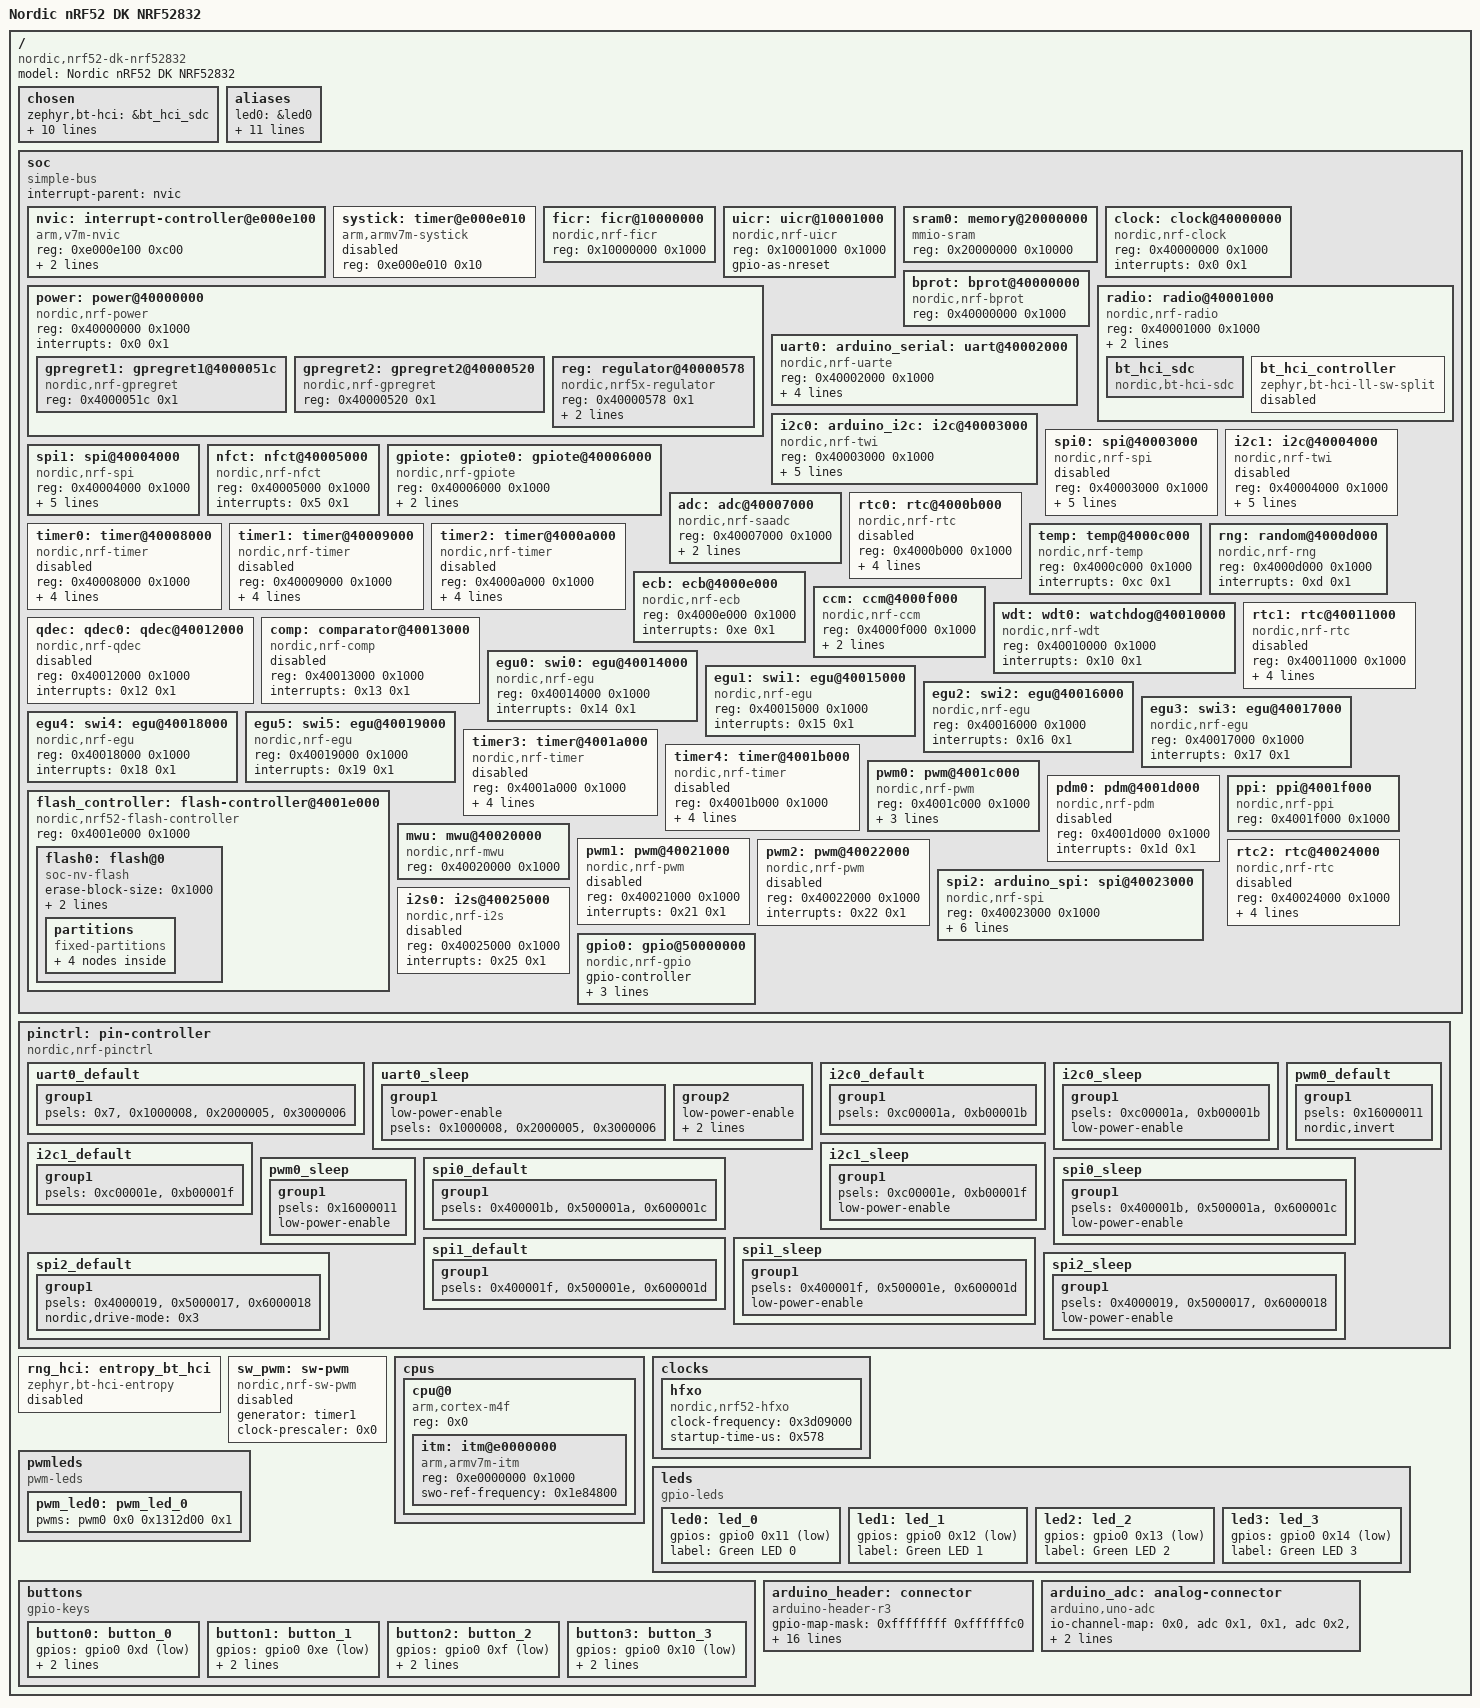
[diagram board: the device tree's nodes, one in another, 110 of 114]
/dts-v1/;

/* node '/' defined in zephyr/dts/common/skeleton.dtsi:9 */
/ {
	#address-cells = < 0x1 >;                /* in zephyr/dts/common/skeleton.dtsi:10 */
	#size-cells = < 0x1 >;                   /* in zephyr/dts/common/skeleton.dtsi:11 */
	model = "Nordic nRF52 DK NRF52832";      /* in zephyr/boards/nordic/nrf52dk/nrf52dk_nrf52832.dts:15 */
	compatible = "nordic,nrf52-dk-nrf52832"; /* in zephyr/boards/nordic/nrf52dk/nrf52dk_nrf52832.dts:16 */

	/* node '/chosen' defined in zephyr/dts/common/skeleton.dtsi:13 */
	chosen {
		zephyr,bt-hci = &bt_hci_sdc;                 /* in zephyr/dts/arm/nordic/nrf52832.dtsi:14 */
		zephyr,entropy = &rng;                       /* in zephyr/dts/arm/nordic/nrf52832.dtsi:15 */
		zephyr,flash-controller = &flash_controller; /* in zephyr/dts/arm/nordic/nrf52832.dtsi:16 */
		zephyr,console = &uart0;                     /* in zephyr/boards/nordic/nrf52dk/nrf52dk_nrf52832.dts:19 */
		zephyr,shell-uart = &uart0;                  /* in zephyr/boards/nordic/nrf52dk/nrf52dk_nrf52832.dts:20 */
		zephyr,uart-mcumgr = &uart0;                 /* in zephyr/boards/nordic/nrf52dk/nrf52dk_nrf52832.dts:21 */
		zephyr,bt-mon-uart = &uart0;                 /* in zephyr/boards/nordic/nrf52dk/nrf52dk_nrf52832.dts:22 */
		zephyr,bt-c2h-uart = &uart0;                 /* in zephyr/boards/nordic/nrf52dk/nrf52dk_nrf52832.dts:23 */
		zephyr,sram = &sram0;                        /* in zephyr/boards/nordic/nrf52dk/nrf52dk_nrf52832.dts:24 */
		zephyr,flash = &flash0;                      /* in zephyr/boards/nordic/nrf52dk/nrf52dk_nrf52832.dts:25 */
		zephyr,code-partition = &slot0_partition;    /* in zephyr/boards/nordic/nrf52dk/nrf52dk_nrf52832.dts:26 */
	};

	/* node '/aliases' defined in zephyr/dts/common/skeleton.dtsi:15 */
	aliases {
		led0 = &led0;               /* in zephyr/boards/nordic/nrf52dk/nrf52dk_nrf52832.dts:131 */
		led1 = &led1;               /* in zephyr/boards/nordic/nrf52dk/nrf52dk_nrf52832.dts:132 */
		led2 = &led2;               /* in zephyr/boards/nordic/nrf52dk/nrf52dk_nrf52832.dts:133 */
		led3 = &led3;               /* in zephyr/boards/nordic/nrf52dk/nrf52dk_nrf52832.dts:134 */
		pwm-led0 = &pwm_led0;       /* in zephyr/boards/nordic/nrf52dk/nrf52dk_nrf52832.dts:135 */
		sw0 = &button0;             /* in zephyr/boards/nordic/nrf52dk/nrf52dk_nrf52832.dts:136 */
		sw1 = &button1;             /* in zephyr/boards/nordic/nrf52dk/nrf52dk_nrf52832.dts:137 */
		sw2 = &button2;             /* in zephyr/boards/nordic/nrf52dk/nrf52dk_nrf52832.dts:138 */
		sw3 = &button3;             /* in zephyr/boards/nordic/nrf52dk/nrf52dk_nrf52832.dts:139 */
		mcuboot-button0 = &button0; /* in zephyr/boards/nordic/nrf52dk/nrf52dk_nrf52832.dts:140 */
		mcuboot-led0 = &led0;       /* in zephyr/boards/nordic/nrf52dk/nrf52dk_nrf52832.dts:141 */
		watchdog0 = &wdt0;          /* in zephyr/boards/nordic/nrf52dk/nrf52dk_nrf52832.dts:142 */
	};

	/* node '/soc' defined in zephyr/dts/arm/armv7-m.dtsi:6 */
	soc {
		#address-cells = < 0x1 >;     /* in zephyr/dts/arm/armv7-m.dtsi:7 */
		#size-cells = < 0x1 >;        /* in zephyr/dts/arm/armv7-m.dtsi:8 */
		interrupt-parent = < &nvic >; /* in zephyr/dts/arm/armv7-m.dtsi:10 */
		ranges;                       /* in zephyr/dts/arm/armv7-m.dtsi:11 */
		compatible = "simple-bus";    /* in zephyr/dts/arm/nordic/nrf52832_qfaa.dtsi:21 */

		/* node '/soc/interrupt-controller@e000e100' defined in zephyr/dts/arm/armv7-m.dtsi:13 */
		nvic: interrupt-controller@e000e100 {
			#address-cells = < 0x1 >;            /* in zephyr/dts/arm/armv7-m.dtsi:14 */
			compatible = "arm,v7m-nvic";         /* in zephyr/dts/arm/armv7-m.dtsi:15 */
			reg = < 0xe000e100 0xc00 >;          /* in zephyr/dts/arm/armv7-m.dtsi:16 */
			interrupt-controller;                /* in zephyr/dts/arm/armv7-m.dtsi:17 */
			#interrupt-cells = < 0x2 >;          /* in zephyr/dts/arm/armv7-m.dtsi:18 */
			arm,num-irq-priority-bits = < 0x3 >; /* in zephyr/dts/arm/nordic/nrf52832.dtsi:510 */
			phandle = < 0x1 >;                   /* in zephyr/dts/arm/armv7-m.dtsi:10 */
		};

		/* node '/soc/timer@e000e010' defined in zephyr/dts/arm/armv7-m.dtsi:21 */
		systick: timer@e000e010 {
			compatible = "arm,armv7m-systick"; /* in zephyr/dts/arm/armv7-m.dtsi:22 */
			reg = < 0xe000e010 0x10 >;         /* in zephyr/dts/arm/armv7-m.dtsi:23 */
			status = "disabled";               /* in zephyr/dts/arm/nordic/nrf52832.dtsi:515 */
		};

		/* node '/soc/ficr@10000000' defined in zephyr/dts/arm/nordic/nrf52832.dtsi:48 */
		ficr: ficr@10000000 {
			compatible = "nordic,nrf-ficr"; /* in zephyr/dts/arm/nordic/nrf52832.dtsi:49 */
			reg = < 0x10000000 0x1000 >;    /* in zephyr/dts/arm/nordic/nrf52832.dtsi:50 */
			#nordic,ficr-cells = < 0x1 >;   /* in zephyr/dts/arm/nordic/nrf52832.dtsi:51 */
			status = "okay";                /* in zephyr/dts/arm/nordic/nrf52832.dtsi:52 */
		};

		/* node '/soc/uicr@10001000' defined in zephyr/dts/arm/nordic/nrf52832.dtsi:55 */
		uicr: uicr@10001000 {
			compatible = "nordic,nrf-uicr";     /* in zephyr/dts/arm/nordic/nrf52832.dtsi:56 */
			reg = < 0x10001000 0x1000 >;        /* in zephyr/dts/arm/nordic/nrf52832.dtsi:57 */
			ranges = < 0x0 0x10001000 0x1000 >; /* in zephyr/dts/arm/nordic/nrf52832.dtsi:58 */
			status = "okay";                    /* in zephyr/dts/arm/nordic/nrf52832.dtsi:59 */
			#address-cells = < 0x1 >;           /* in zephyr/dts/arm/nordic/nrf52832.dtsi:60 */
			#size-cells = < 0x1 >;              /* in zephyr/dts/arm/nordic/nrf52832.dtsi:61 */
			gpio-as-nreset;                     /* in zephyr/boards/nordic/nrf52dk/nrf52dk_nrf52832.dts:155 */
		};

		/* node '/soc/memory@20000000' defined in zephyr/dts/arm/nordic/nrf52832.dtsi:64 */
		sram0: memory@20000000 {
			compatible = "mmio-sram";            /* in zephyr/dts/arm/nordic/nrf52832.dtsi:65 */
			#address-cells = < 0x1 >;            /* in zephyr/dts/arm/nordic/nrf52832.dtsi:66 */
			#size-cells = < 0x1 >;               /* in zephyr/dts/arm/nordic/nrf52832.dtsi:67 */
			reg = < 0x20000000 0x10000 >;        /* in zephyr/dts/arm/nordic/nrf52832_qfaa.dtsi:15 */
			ranges = < 0x0 0x20000000 0x10000 >; /* in zephyr/dts/arm/nordic/nrf52832_qfaa.dtsi:16 */
		};

		/* node '/soc/clock@40000000' defined in zephyr/dts/arm/nordic/nrf52832.dtsi:70 */
		clock: clock@40000000 {
			compatible = "nordic,nrf-clock"; /* in zephyr/dts/arm/nordic/nrf52832.dtsi:71 */
			reg = < 0x40000000 0x1000 >;     /* in zephyr/dts/arm/nordic/nrf52832.dtsi:72 */
			interrupts = < 0x0 0x1 >;        /* in zephyr/dts/arm/nordic/nrf52832.dtsi:73 */
			status = "okay";                 /* in zephyr/dts/arm/nordic/nrf52832.dtsi:74 */
		};

		/* node '/soc/power@40000000' defined in zephyr/dts/arm/nordic/nrf52832.dtsi:77 */
		power: power@40000000 {
			compatible = "nordic,nrf-power"; /* in zephyr/dts/arm/nordic/nrf52832.dtsi:78 */
			reg = < 0x40000000 0x1000 >;     /* in zephyr/dts/arm/nordic/nrf52832.dtsi:79 */
			interrupts = < 0x0 0x1 >;        /* in zephyr/dts/arm/nordic/nrf52832.dtsi:80 */
			status = "okay";                 /* in zephyr/dts/arm/nordic/nrf52832.dtsi:81 */
			#address-cells = < 0x1 >;        /* in zephyr/dts/arm/nordic/nrf52832.dtsi:82 */
			#size-cells = < 0x1 >;           /* in zephyr/dts/arm/nordic/nrf52832.dtsi:83 */

			/* node '/soc/power@40000000/gpregret1@4000051c' defined in zephyr/dts/arm/nordic/nrf52832.dtsi:85 */
			gpregret1: gpregret1@4000051c {
				#address-cells = < 0x1 >;           /* in zephyr/dts/arm/nordic/nrf52832.dtsi:86 */
				#size-cells = < 0x1 >;              /* in zephyr/dts/arm/nordic/nrf52832.dtsi:87 */
				compatible = "nordic,nrf-gpregret"; /* in zephyr/dts/arm/nordic/nrf52832.dtsi:88 */
				reg = < 0x4000051c 0x1 >;           /* in zephyr/dts/arm/nordic/nrf52832.dtsi:89 */
				status = "okay";                    /* in zephyr/dts/arm/nordic/nrf52832.dtsi:90 */
			};

			/* node '/soc/power@40000000/gpregret2@40000520' defined in zephyr/dts/arm/nordic/nrf52832.dtsi:93 */
			gpregret2: gpregret2@40000520 {
				#address-cells = < 0x1 >;           /* in zephyr/dts/arm/nordic/nrf52832.dtsi:94 */
				#size-cells = < 0x1 >;              /* in zephyr/dts/arm/nordic/nrf52832.dtsi:95 */
				compatible = "nordic,nrf-gpregret"; /* in zephyr/dts/arm/nordic/nrf52832.dtsi:96 */
				reg = < 0x40000520 0x1 >;           /* in zephyr/dts/arm/nordic/nrf52832.dtsi:97 */
				status = "okay";                    /* in zephyr/dts/arm/nordic/nrf52832.dtsi:98 */
			};

			/* node '/soc/power@40000000/regulator@40000578' defined in zephyr/dts/arm/nordic/nrf52832.dtsi:101 */
			reg: regulator@40000578 {
				compatible = "nordic,nrf5x-regulator"; /* in zephyr/dts/arm/nordic/nrf52832.dtsi:102 */
				reg = < 0x40000578 0x1 >;              /* in zephyr/dts/arm/nordic/nrf52832.dtsi:103 */
				regulator-name = "REG";                /* in zephyr/dts/arm/nordic/nrf52832.dtsi:104 */
				regulator-initial-mode = < 0x1 >;      /* in zephyr/boards/nordic/nrf52dk/nrf52dk_nrf52832.dts:147 */
			};
		};

		/* node '/soc/bprot@40000000' defined in zephyr/dts/arm/nordic/nrf52832.dtsi:109 */
		bprot: bprot@40000000 {
			compatible = "nordic,nrf-bprot"; /* in zephyr/dts/arm/nordic/nrf52832.dtsi:110 */
			reg = < 0x40000000 0x1000 >;     /* in zephyr/dts/arm/nordic/nrf52832.dtsi:111 */
			status = "okay";                 /* in zephyr/dts/arm/nordic/nrf52832.dtsi:112 */
		};

		/* node '/soc/radio@40001000' defined in zephyr/dts/arm/nordic/nrf52832.dtsi:115 */
		radio: radio@40001000 {
			compatible = "nordic,nrf-radio"; /* in zephyr/dts/arm/nordic/nrf52832.dtsi:116 */
			reg = < 0x40001000 0x1000 >;     /* in zephyr/dts/arm/nordic/nrf52832.dtsi:117 */
			interrupts = < 0x1 0x1 >;        /* in zephyr/dts/arm/nordic/nrf52832.dtsi:118 */
			status = "okay";                 /* in zephyr/dts/arm/nordic/nrf52832.dtsi:119 */
			ble-2mbps-supported;             /* in zephyr/dts/arm/nordic/nrf52832.dtsi:120 */

			/* node '/soc/radio@40001000/bt_hci_sdc' defined in zephyr/dts/arm/nordic/nrf52832.dtsi:122 */
			bt_hci_sdc: bt_hci_sdc {
				compatible = "nordic,bt-hci-sdc"; /* in zephyr/dts/arm/nordic/nrf52832.dtsi:123 */
				status = "okay";                  /* in zephyr/dts/arm/nordic/nrf52832.dtsi:124 */
			};

			/* node '/soc/radio@40001000/bt_hci_controller' defined in zephyr/dts/arm/nordic/nrf52832.dtsi:126 */
			bt_hci_controller: bt_hci_controller {
				compatible = "zephyr,bt-hci-ll-sw-split"; /* in zephyr/dts/arm/nordic/nrf52832.dtsi:127 */
				status = "disabled";                      /* in zephyr/dts/arm/nordic/nrf52832.dtsi:128 */
			};
		};

		/* node '/soc/uart@40002000' defined in zephyr/dts/arm/nordic/nrf52832.dtsi:132 */
		uart0: arduino_serial: uart@40002000 {
			reg = < 0x40002000 0x1000 >;     /* in zephyr/dts/arm/nordic/nrf52832.dtsi:136 */
			interrupts = < 0x2 0x1 >;        /* in zephyr/dts/arm/nordic/nrf52832.dtsi:137 */
			status = "okay";                 /* in zephyr/boards/nordic/nrf52dk/nrf52dk_nrf52832.dts:171 */
			compatible = "nordic,nrf-uarte"; /* in zephyr/boards/nordic/nrf52dk/nrf52dk_nrf52832.dts:172 */
			current-speed = < 0x1c200 >;     /* in zephyr/boards/nordic/nrf52dk/nrf52dk_nrf52832.dts:173 */
			pinctrl-0 = < &uart0_default >;  /* in zephyr/boards/nordic/nrf52dk/nrf52dk_nrf52832.dts:174 */
			pinctrl-1 = < &uart0_sleep >;    /* in zephyr/boards/nordic/nrf52dk/nrf52dk_nrf52832.dts:175 */
			pinctrl-names = "default",
			                "sleep";         /* in zephyr/boards/nordic/nrf52dk/nrf52dk_nrf52832.dts:176 */
		};

		/* node '/soc/i2c@40003000' defined in zephyr/dts/arm/nordic/nrf52832.dtsi:141 */
		i2c0: arduino_i2c: i2c@40003000 {
			#address-cells = < 0x1 >;      /* in zephyr/dts/arm/nordic/nrf52832.dtsi:150 */
			#size-cells = < 0x0 >;         /* in zephyr/dts/arm/nordic/nrf52832.dtsi:151 */
			reg = < 0x40003000 0x1000 >;   /* in zephyr/dts/arm/nordic/nrf52832.dtsi:152 */
			interrupts = < 0x3 0x1 >;      /* in zephyr/dts/arm/nordic/nrf52832.dtsi:153 */
			easydma-maxcnt-bits = < 0x8 >; /* in zephyr/dts/arm/nordic/nrf52832.dtsi:154 */
			zephyr,pm-device-runtime-auto; /* in zephyr/dts/arm/nordic/nrf52832.dtsi:156 */
			compatible = "nordic,nrf-twi"; /* in zephyr/boards/nordic/nrf52dk/nrf52dk_nrf52832.dts:180 */
			status = "okay";               /* in zephyr/boards/nordic/nrf52dk/nrf52dk_nrf52832.dts:181 */
			pinctrl-0 = < &i2c0_default >; /* in zephyr/boards/nordic/nrf52dk/nrf52dk_nrf52832.dts:182 */
			pinctrl-1 = < &i2c0_sleep >;   /* in zephyr/boards/nordic/nrf52dk/nrf52dk_nrf52832.dts:183 */
			pinctrl-names = "default",
			                "sleep";       /* in zephyr/boards/nordic/nrf52dk/nrf52dk_nrf52832.dts:184 */
		};

		/* node '/soc/spi@40003000' defined in zephyr/dts/arm/nordic/nrf52832.dtsi:159 */
		spi0: spi@40003000 {
			#address-cells = < 0x1 >;      /* in zephyr/dts/arm/nordic/nrf52832.dtsi:168 */
			#size-cells = < 0x0 >;         /* in zephyr/dts/arm/nordic/nrf52832.dtsi:169 */
			reg = < 0x40003000 0x1000 >;   /* in zephyr/dts/arm/nordic/nrf52832.dtsi:170 */
			interrupts = < 0x3 0x1 >;      /* in zephyr/dts/arm/nordic/nrf52832.dtsi:171 */
			max-frequency = < 0x7a1200 >;  /* in zephyr/dts/arm/nordic/nrf52832.dtsi:172 */
			easydma-maxcnt-bits = < 0x8 >; /* in zephyr/dts/arm/nordic/nrf52832.dtsi:173 */
			status = "disabled";           /* in zephyr/dts/arm/nordic/nrf52832.dtsi:174 */
			compatible = "nordic,nrf-spi"; /* in zephyr/boards/nordic/nrf52dk/nrf52dk_nrf52832.dts:204 */
			pinctrl-0 = < &spi0_default >; /* in zephyr/boards/nordic/nrf52dk/nrf52dk_nrf52832.dts:207 */
			pinctrl-1 = < &spi0_sleep >;   /* in zephyr/boards/nordic/nrf52dk/nrf52dk_nrf52832.dts:208 */
			pinctrl-names = "default",
			                "sleep";       /* in zephyr/boards/nordic/nrf52dk/nrf52dk_nrf52832.dts:209 */
		};

		/* node '/soc/i2c@40004000' defined in zephyr/dts/arm/nordic/nrf52832.dtsi:177 */
		i2c1: i2c@40004000 {
			#address-cells = < 0x1 >;      /* in zephyr/dts/arm/nordic/nrf52832.dtsi:186 */
			#size-cells = < 0x0 >;         /* in zephyr/dts/arm/nordic/nrf52832.dtsi:187 */
			reg = < 0x40004000 0x1000 >;   /* in zephyr/dts/arm/nordic/nrf52832.dtsi:188 */
			interrupts = < 0x4 0x1 >;      /* in zephyr/dts/arm/nordic/nrf52832.dtsi:189 */
			easydma-maxcnt-bits = < 0x8 >; /* in zephyr/dts/arm/nordic/nrf52832.dtsi:190 */
			status = "disabled";           /* in zephyr/dts/arm/nordic/nrf52832.dtsi:191 */
			zephyr,pm-device-runtime-auto; /* in zephyr/dts/arm/nordic/nrf52832.dtsi:192 */
			compatible = "nordic,nrf-twi"; /* in zephyr/boards/nordic/nrf52dk/nrf52dk_nrf52832.dts:188 */
			pinctrl-0 = < &i2c1_default >; /* in zephyr/boards/nordic/nrf52dk/nrf52dk_nrf52832.dts:191 */
			pinctrl-1 = < &i2c1_sleep >;   /* in zephyr/boards/nordic/nrf52dk/nrf52dk_nrf52832.dts:192 */
			pinctrl-names = "default",
			                "sleep";       /* in zephyr/boards/nordic/nrf52dk/nrf52dk_nrf52832.dts:193 */
		};

		/* node '/soc/spi@40004000' defined in zephyr/dts/arm/nordic/nrf52832.dtsi:195 */
		spi1: spi@40004000 {
			#address-cells = < 0x1 >;      /* in zephyr/dts/arm/nordic/nrf52832.dtsi:204 */
			#size-cells = < 0x0 >;         /* in zephyr/dts/arm/nordic/nrf52832.dtsi:205 */
			reg = < 0x40004000 0x1000 >;   /* in zephyr/dts/arm/nordic/nrf52832.dtsi:206 */
			interrupts = < 0x4 0x1 >;      /* in zephyr/dts/arm/nordic/nrf52832.dtsi:207 */
			max-frequency = < 0x7a1200 >;  /* in zephyr/dts/arm/nordic/nrf52832.dtsi:208 */
			easydma-maxcnt-bits = < 0x8 >; /* in zephyr/dts/arm/nordic/nrf52832.dtsi:209 */
			compatible = "nordic,nrf-spi"; /* in zephyr/boards/nordic/nrf52dk/nrf52dk_nrf52832.dts:213 */
			status = "okay";               /* in zephyr/boards/nordic/nrf52dk/nrf52dk_nrf52832.dts:214 */
			pinctrl-0 = < &spi1_default >; /* in zephyr/boards/nordic/nrf52dk/nrf52dk_nrf52832.dts:215 */
			pinctrl-1 = < &spi1_sleep >;   /* in zephyr/boards/nordic/nrf52dk/nrf52dk_nrf52832.dts:216 */
			pinctrl-names = "default",
			                "sleep";       /* in zephyr/boards/nordic/nrf52dk/nrf52dk_nrf52832.dts:217 */
		};

		/* node '/soc/nfct@40005000' defined in zephyr/dts/arm/nordic/nrf52832.dtsi:213 */
		nfct: nfct@40005000 {
			compatible = "nordic,nrf-nfct"; /* in zephyr/dts/arm/nordic/nrf52832.dtsi:214 */
			reg = < 0x40005000 0x1000 >;    /* in zephyr/dts/arm/nordic/nrf52832.dtsi:215 */
			interrupts = < 0x5 0x1 >;       /* in zephyr/dts/arm/nordic/nrf52832.dtsi:216 */
			status = "okay";                /* in zephyr/boards/nordic/nrf52dk/nrf52dk_nrf52832.dts:159 */
		};

		/* node '/soc/gpiote@40006000' defined in zephyr/dts/arm/nordic/nrf52832.dtsi:220 */
		gpiote: gpiote0: gpiote@40006000 {
			compatible = "nordic,nrf-gpiote"; /* in zephyr/dts/arm/nordic/nrf52832.dtsi:221 */
			reg = < 0x40006000 0x1000 >;      /* in zephyr/dts/arm/nordic/nrf52832.dtsi:222 */
			interrupts = < 0x6 0x5 >;         /* in zephyr/dts/arm/nordic/nrf52832.dtsi:223 */
			instance = < 0x0 >;               /* in zephyr/dts/arm/nordic/nrf52832.dtsi:225 */
			status = "okay";                  /* in zephyr/boards/nordic/nrf52dk/nrf52dk_nrf52832.dts:163 */
			phandle = < 0x11 >;               /* in zephyr/dts/arm/nordic/nrf52832.dtsi:504 */
		};

		/* node '/soc/adc@40007000' defined in zephyr/dts/arm/nordic/nrf52832.dtsi:228 */
		adc: adc@40007000 {
			compatible = "nordic,nrf-saadc"; /* in zephyr/dts/arm/nordic/nrf52832.dtsi:229 */
			reg = < 0x40007000 0x1000 >;     /* in zephyr/dts/arm/nordic/nrf52832.dtsi:230 */
			interrupts = < 0x7 0x1 >;        /* in zephyr/dts/arm/nordic/nrf52832.dtsi:231 */
			#io-channel-cells = < 0x1 >;     /* in zephyr/dts/arm/nordic/nrf52832.dtsi:233 */
			zephyr,pm-device-runtime-auto;   /* in zephyr/dts/arm/nordic/nrf52832.dtsi:234 */
			status = "okay";                 /* in zephyr/boards/nordic/nrf52dk/nrf52dk_nrf52832.dts:151 */
			phandle = < 0x15 >;              /* in zephyr/boards/nordic/nrf52dk/nrf52dk_nrf52832.dts:121 */
		};

		/* node '/soc/timer@40008000' defined in zephyr/dts/arm/nordic/nrf52832.dtsi:237 */
		timer0: timer@40008000 {
			compatible = "nordic,nrf-timer"; /* in zephyr/dts/arm/nordic/nrf52832.dtsi:238 */
			status = "disabled";             /* in zephyr/dts/arm/nordic/nrf52832.dtsi:239 */
			reg = < 0x40008000 0x1000 >;     /* in zephyr/dts/arm/nordic/nrf52832.dtsi:240 */
			cc-num = < 0x4 >;                /* in zephyr/dts/arm/nordic/nrf52832.dtsi:241 */
			max-bit-width = < 0x20 >;        /* in zephyr/dts/arm/nordic/nrf52832.dtsi:242 */
			interrupts = < 0x8 0x1 >;        /* in zephyr/dts/arm/nordic/nrf52832.dtsi:243 */
			prescaler = < 0x0 >;             /* in zephyr/dts/arm/nordic/nrf52832.dtsi:244 */
		};

		/* node '/soc/timer@40009000' defined in zephyr/dts/arm/nordic/nrf52832.dtsi:247 */
		timer1: timer@40009000 {
			compatible = "nordic,nrf-timer"; /* in zephyr/dts/arm/nordic/nrf52832.dtsi:248 */
			status = "disabled";             /* in zephyr/dts/arm/nordic/nrf52832.dtsi:249 */
			reg = < 0x40009000 0x1000 >;     /* in zephyr/dts/arm/nordic/nrf52832.dtsi:250 */
			cc-num = < 0x4 >;                /* in zephyr/dts/arm/nordic/nrf52832.dtsi:251 */
			max-bit-width = < 0x20 >;        /* in zephyr/dts/arm/nordic/nrf52832.dtsi:252 */
			interrupts = < 0x9 0x1 >;        /* in zephyr/dts/arm/nordic/nrf52832.dtsi:253 */
			prescaler = < 0x0 >;             /* in zephyr/dts/arm/nordic/nrf52832.dtsi:254 */
			phandle = < 0x12 >;              /* in zephyr/dts/vendor/nordic/nrf_common.dtsi:42 */
		};

		/* node '/soc/timer@4000a000' defined in zephyr/dts/arm/nordic/nrf52832.dtsi:257 */
		timer2: timer@4000a000 {
			compatible = "nordic,nrf-timer"; /* in zephyr/dts/arm/nordic/nrf52832.dtsi:258 */
			status = "disabled";             /* in zephyr/dts/arm/nordic/nrf52832.dtsi:259 */
			reg = < 0x4000a000 0x1000 >;     /* in zephyr/dts/arm/nordic/nrf52832.dtsi:260 */
			cc-num = < 0x4 >;                /* in zephyr/dts/arm/nordic/nrf52832.dtsi:261 */
			max-bit-width = < 0x20 >;        /* in zephyr/dts/arm/nordic/nrf52832.dtsi:262 */
			interrupts = < 0xa 0x1 >;        /* in zephyr/dts/arm/nordic/nrf52832.dtsi:263 */
			prescaler = < 0x0 >;             /* in zephyr/dts/arm/nordic/nrf52832.dtsi:264 */
		};

		/* node '/soc/rtc@4000b000' defined in zephyr/dts/arm/nordic/nrf52832.dtsi:267 */
		rtc0: rtc@4000b000 {
			compatible = "nordic,nrf-rtc"; /* in zephyr/dts/arm/nordic/nrf52832.dtsi:268 */
			reg = < 0x4000b000 0x1000 >;   /* in zephyr/dts/arm/nordic/nrf52832.dtsi:269 */
			cc-num = < 0x3 >;              /* in zephyr/dts/arm/nordic/nrf52832.dtsi:270 */
			interrupts = < 0xb 0x1 >;      /* in zephyr/dts/arm/nordic/nrf52832.dtsi:271 */
			status = "disabled";           /* in zephyr/dts/arm/nordic/nrf52832.dtsi:272 */
			clock-frequency = < 0x8000 >;  /* in zephyr/dts/arm/nordic/nrf52832.dtsi:273 */
			prescaler = < 0x1 >;           /* in zephyr/dts/arm/nordic/nrf52832.dtsi:274 */
		};

		/* node '/soc/temp@4000c000' defined in zephyr/dts/arm/nordic/nrf52832.dtsi:277 */
		temp: temp@4000c000 {
			compatible = "nordic,nrf-temp"; /* in zephyr/dts/arm/nordic/nrf52832.dtsi:278 */
			reg = < 0x4000c000 0x1000 >;    /* in zephyr/dts/arm/nordic/nrf52832.dtsi:279 */
			interrupts = < 0xc 0x1 >;       /* in zephyr/dts/arm/nordic/nrf52832.dtsi:280 */
			status = "okay";                /* in zephyr/dts/arm/nordic/nrf52832.dtsi:281 */
		};

		/* node '/soc/random@4000d000' defined in zephyr/dts/arm/nordic/nrf52832.dtsi:284 */
		rng: random@4000d000 {
			compatible = "nordic,nrf-rng"; /* in zephyr/dts/arm/nordic/nrf52832.dtsi:285 */
			reg = < 0x4000d000 0x1000 >;   /* in zephyr/dts/arm/nordic/nrf52832.dtsi:286 */
			interrupts = < 0xd 0x1 >;      /* in zephyr/dts/arm/nordic/nrf52832.dtsi:287 */
			status = "okay";               /* in zephyr/dts/arm/nordic/nrf52832.dtsi:288 */
		};

		/* node '/soc/ecb@4000e000' defined in zephyr/dts/arm/nordic/nrf52832.dtsi:291 */
		ecb: ecb@4000e000 {
			compatible = "nordic,nrf-ecb"; /* in zephyr/dts/arm/nordic/nrf52832.dtsi:292 */
			reg = < 0x4000e000 0x1000 >;   /* in zephyr/dts/arm/nordic/nrf52832.dtsi:293 */
			interrupts = < 0xe 0x1 >;      /* in zephyr/dts/arm/nordic/nrf52832.dtsi:294 */
			status = "okay";               /* in zephyr/dts/arm/nordic/nrf52832.dtsi:295 */
		};

		/* node '/soc/ccm@4000f000' defined in zephyr/dts/arm/nordic/nrf52832.dtsi:298 */
		ccm: ccm@4000f000 {
			compatible = "nordic,nrf-ccm"; /* in zephyr/dts/arm/nordic/nrf52832.dtsi:299 */
			reg = < 0x4000f000 0x1000 >;   /* in zephyr/dts/arm/nordic/nrf52832.dtsi:300 */
			interrupts = < 0xf 0x1 >;      /* in zephyr/dts/arm/nordic/nrf52832.dtsi:301 */
			length-field-length-8-bits;    /* in zephyr/dts/arm/nordic/nrf52832.dtsi:302 */
			status = "okay";               /* in zephyr/dts/arm/nordic/nrf52832.dtsi:303 */
		};

		/* node '/soc/watchdog@40010000' defined in zephyr/dts/arm/nordic/nrf52832.dtsi:306 */
		wdt: wdt0: watchdog@40010000 {
			compatible = "nordic,nrf-wdt"; /* in zephyr/dts/arm/nordic/nrf52832.dtsi:307 */
			reg = < 0x40010000 0x1000 >;   /* in zephyr/dts/arm/nordic/nrf52832.dtsi:308 */
			interrupts = < 0x10 0x1 >;     /* in zephyr/dts/arm/nordic/nrf52832.dtsi:309 */
			status = "okay";               /* in zephyr/dts/arm/nordic/nrf52832.dtsi:310 */
		};

		/* node '/soc/rtc@40011000' defined in zephyr/dts/arm/nordic/nrf52832.dtsi:313 */
		rtc1: rtc@40011000 {
			compatible = "nordic,nrf-rtc"; /* in zephyr/dts/arm/nordic/nrf52832.dtsi:314 */
			reg = < 0x40011000 0x1000 >;   /* in zephyr/dts/arm/nordic/nrf52832.dtsi:315 */
			cc-num = < 0x4 >;              /* in zephyr/dts/arm/nordic/nrf52832.dtsi:316 */
			interrupts = < 0x11 0x1 >;     /* in zephyr/dts/arm/nordic/nrf52832.dtsi:317 */
			status = "disabled";           /* in zephyr/dts/arm/nordic/nrf52832.dtsi:318 */
			clock-frequency = < 0x8000 >;  /* in zephyr/dts/arm/nordic/nrf52832.dtsi:319 */
			prescaler = < 0x1 >;           /* in zephyr/dts/arm/nordic/nrf52832.dtsi:320 */
		};

		/* node '/soc/qdec@40012000' defined in zephyr/dts/arm/nordic/nrf52832.dtsi:323 */
		qdec: qdec0: qdec@40012000 {
			compatible = "nordic,nrf-qdec"; /* in zephyr/dts/arm/nordic/nrf52832.dtsi:324 */
			reg = < 0x40012000 0x1000 >;    /* in zephyr/dts/arm/nordic/nrf52832.dtsi:325 */
			interrupts = < 0x12 0x1 >;      /* in zephyr/dts/arm/nordic/nrf52832.dtsi:326 */
			status = "disabled";            /* in zephyr/dts/arm/nordic/nrf52832.dtsi:327 */
		};

		/* node '/soc/comparator@40013000' defined in zephyr/dts/arm/nordic/nrf52832.dtsi:330 */
		comp: comparator@40013000 {
			compatible = "nordic,nrf-comp"; /* in zephyr/dts/arm/nordic/nrf52832.dtsi:335 */
			reg = < 0x40013000 0x1000 >;    /* in zephyr/dts/arm/nordic/nrf52832.dtsi:336 */
			interrupts = < 0x13 0x1 >;      /* in zephyr/dts/arm/nordic/nrf52832.dtsi:337 */
			status = "disabled";            /* in zephyr/dts/arm/nordic/nrf52832.dtsi:338 */
		};

		/* node '/soc/egu@40014000' defined in zephyr/dts/arm/nordic/nrf52832.dtsi:341 */
		egu0: swi0: egu@40014000 {
			compatible = "nordic,nrf-egu",
			             "nordic,nrf-swi"; /* in zephyr/dts/arm/nordic/nrf52832.dtsi:342 */
			reg = < 0x40014000 0x1000 >;   /* in zephyr/dts/arm/nordic/nrf52832.dtsi:343 */
			interrupts = < 0x14 0x1 >;     /* in zephyr/dts/arm/nordic/nrf52832.dtsi:344 */
			status = "okay";               /* in zephyr/dts/arm/nordic/nrf52832.dtsi:345 */
		};

		/* node '/soc/egu@40015000' defined in zephyr/dts/arm/nordic/nrf52832.dtsi:348 */
		egu1: swi1: egu@40015000 {
			compatible = "nordic,nrf-egu",
			             "nordic,nrf-swi"; /* in zephyr/dts/arm/nordic/nrf52832.dtsi:349 */
			reg = < 0x40015000 0x1000 >;   /* in zephyr/dts/arm/nordic/nrf52832.dtsi:350 */
			interrupts = < 0x15 0x1 >;     /* in zephyr/dts/arm/nordic/nrf52832.dtsi:351 */
			status = "okay";               /* in zephyr/dts/arm/nordic/nrf52832.dtsi:352 */
		};

		/* node '/soc/egu@40016000' defined in zephyr/dts/arm/nordic/nrf52832.dtsi:355 */
		egu2: swi2: egu@40016000 {
			compatible = "nordic,nrf-egu",
			             "nordic,nrf-swi"; /* in zephyr/dts/arm/nordic/nrf52832.dtsi:356 */
			reg = < 0x40016000 0x1000 >;   /* in zephyr/dts/arm/nordic/nrf52832.dtsi:357 */
			interrupts = < 0x16 0x1 >;     /* in zephyr/dts/arm/nordic/nrf52832.dtsi:358 */
			status = "okay";               /* in zephyr/dts/arm/nordic/nrf52832.dtsi:359 */
		};

		/* node '/soc/egu@40017000' defined in zephyr/dts/arm/nordic/nrf52832.dtsi:362 */
		egu3: swi3: egu@40017000 {
			compatible = "nordic,nrf-egu",
			             "nordic,nrf-swi"; /* in zephyr/dts/arm/nordic/nrf52832.dtsi:363 */
			reg = < 0x40017000 0x1000 >;   /* in zephyr/dts/arm/nordic/nrf52832.dtsi:364 */
			interrupts = < 0x17 0x1 >;     /* in zephyr/dts/arm/nordic/nrf52832.dtsi:365 */
			status = "okay";               /* in zephyr/dts/arm/nordic/nrf52832.dtsi:366 */
		};

		/* node '/soc/egu@40018000' defined in zephyr/dts/arm/nordic/nrf52832.dtsi:369 */
		egu4: swi4: egu@40018000 {
			compatible = "nordic,nrf-egu",
			             "nordic,nrf-swi"; /* in zephyr/dts/arm/nordic/nrf52832.dtsi:370 */
			reg = < 0x40018000 0x1000 >;   /* in zephyr/dts/arm/nordic/nrf52832.dtsi:371 */
			interrupts = < 0x18 0x1 >;     /* in zephyr/dts/arm/nordic/nrf52832.dtsi:372 */
			status = "okay";               /* in zephyr/dts/arm/nordic/nrf52832.dtsi:373 */
		};

		/* node '/soc/egu@40019000' defined in zephyr/dts/arm/nordic/nrf52832.dtsi:376 */
		egu5: swi5: egu@40019000 {
			compatible = "nordic,nrf-egu",
			             "nordic,nrf-swi"; /* in zephyr/dts/arm/nordic/nrf52832.dtsi:377 */
			reg = < 0x40019000 0x1000 >;   /* in zephyr/dts/arm/nordic/nrf52832.dtsi:378 */
			interrupts = < 0x19 0x1 >;     /* in zephyr/dts/arm/nordic/nrf52832.dtsi:379 */
			status = "okay";               /* in zephyr/dts/arm/nordic/nrf52832.dtsi:380 */
		};

		/* node '/soc/timer@4001a000' defined in zephyr/dts/arm/nordic/nrf52832.dtsi:383 */
		timer3: timer@4001a000 {
			compatible = "nordic,nrf-timer"; /* in zephyr/dts/arm/nordic/nrf52832.dtsi:384 */
			status = "disabled";             /* in zephyr/dts/arm/nordic/nrf52832.dtsi:385 */
			reg = < 0x4001a000 0x1000 >;     /* in zephyr/dts/arm/nordic/nrf52832.dtsi:386 */
			cc-num = < 0x6 >;                /* in zephyr/dts/arm/nordic/nrf52832.dtsi:387 */
			max-bit-width = < 0x20 >;        /* in zephyr/dts/arm/nordic/nrf52832.dtsi:388 */
			interrupts = < 0x1a 0x1 >;       /* in zephyr/dts/arm/nordic/nrf52832.dtsi:389 */
			prescaler = < 0x0 >;             /* in zephyr/dts/arm/nordic/nrf52832.dtsi:390 */
		};

		/* node '/soc/timer@4001b000' defined in zephyr/dts/arm/nordic/nrf52832.dtsi:393 */
		timer4: timer@4001b000 {
			compatible = "nordic,nrf-timer"; /* in zephyr/dts/arm/nordic/nrf52832.dtsi:394 */
			status = "disabled";             /* in zephyr/dts/arm/nordic/nrf52832.dtsi:395 */
			reg = < 0x4001b000 0x1000 >;     /* in zephyr/dts/arm/nordic/nrf52832.dtsi:396 */
			cc-num = < 0x6 >;                /* in zephyr/dts/arm/nordic/nrf52832.dtsi:397 */
			max-bit-width = < 0x20 >;        /* in zephyr/dts/arm/nordic/nrf52832.dtsi:398 */
			interrupts = < 0x1b 0x1 >;       /* in zephyr/dts/arm/nordic/nrf52832.dtsi:399 */
			prescaler = < 0x0 >;             /* in zephyr/dts/arm/nordic/nrf52832.dtsi:400 */
		};

		/* node '/soc/pwm@4001c000' defined in zephyr/dts/arm/nordic/nrf52832.dtsi:403 */
		pwm0: pwm@4001c000 {
			compatible = "nordic,nrf-pwm"; /* in zephyr/dts/arm/nordic/nrf52832.dtsi:404 */
			reg = < 0x4001c000 0x1000 >;   /* in zephyr/dts/arm/nordic/nrf52832.dtsi:405 */
			interrupts = < 0x1c 0x1 >;     /* in zephyr/dts/arm/nordic/nrf52832.dtsi:406 */
			#pwm-cells = < 0x3 >;          /* in zephyr/dts/arm/nordic/nrf52832.dtsi:408 */
			status = "okay";               /* in zephyr/boards/nordic/nrf52dk/nrf52dk_nrf52832.dts:197 */
			pinctrl-0 = < &pwm0_default >; /* in zephyr/boards/nordic/nrf52dk/nrf52dk_nrf52832.dts:198 */
			pinctrl-1 = < &pwm0_sleep >;   /* in zephyr/boards/nordic/nrf52dk/nrf52dk_nrf52832.dts:199 */
			pinctrl-names = "default",
			                "sleep";       /* in zephyr/boards/nordic/nrf52dk/nrf52dk_nrf52832.dts:200 */
			phandle = < 0x14 >;            /* in zephyr/boards/nordic/nrf52dk/nrf52dk_nrf52832.dts:57 */
		};

		/* node '/soc/pdm@4001d000' defined in zephyr/dts/arm/nordic/nrf52832.dtsi:411 */
		pdm0: pdm@4001d000 {
			compatible = "nordic,nrf-pdm"; /* in zephyr/dts/arm/nordic/nrf52832.dtsi:412 */
			reg = < 0x4001d000 0x1000 >;   /* in zephyr/dts/arm/nordic/nrf52832.dtsi:413 */
			interrupts = < 0x1d 0x1 >;     /* in zephyr/dts/arm/nordic/nrf52832.dtsi:414 */
			status = "disabled";           /* in zephyr/dts/arm/nordic/nrf52832.dtsi:415 */
		};

		/* node '/soc/flash-controller@4001e000' defined in zephyr/dts/arm/nordic/nrf52832.dtsi:418 */
		flash_controller: flash-controller@4001e000 {
			compatible = "nordic,nrf52-flash-controller"; /* in zephyr/dts/arm/nordic/nrf52832.dtsi:419 */
			reg = < 0x4001e000 0x1000 >;                  /* in zephyr/dts/arm/nordic/nrf52832.dtsi:420 */
			#address-cells = < 0x1 >;                     /* in zephyr/dts/arm/nordic/nrf52832.dtsi:422 */
			#size-cells = < 0x1 >;                        /* in zephyr/dts/arm/nordic/nrf52832.dtsi:423 */

			/* node '/soc/flash-controller@4001e000/flash@0' defined in zephyr/dts/arm/nordic/nrf52832.dtsi:425 */
			flash0: flash@0 {
				compatible = "soc-nv-flash";   /* in zephyr/dts/arm/nordic/nrf52832.dtsi:426 */
				erase-block-size = < 0x1000 >; /* in zephyr/dts/arm/nordic/nrf52832.dtsi:427 */
				write-block-size = < 0x4 >;    /* in zephyr/dts/arm/nordic/nrf52832.dtsi:428 */
				reg = < 0x0 0x80000 >;         /* in zephyr/dts/arm/nordic/nrf52832_qfaa.dtsi:11 */

				/* node '/soc/flash-controller@4001e000/flash@0/partitions' defined in zephyr/boards/nordic/nrf52dk/nrf52dk_nrf52832.dts:230 */
				partitions {
					compatible = "fixed-partitions"; /* in zephyr/boards/nordic/nrf52dk/nrf52dk_nrf52832.dts:231 */
					#address-cells = < 0x1 >;        /* in zephyr/boards/nordic/nrf52dk/nrf52dk_nrf52832.dts:232 */
					#size-cells = < 0x1 >;           /* in zephyr/boards/nordic/nrf52dk/nrf52dk_nrf52832.dts:233 */

					/* node '/soc/flash-controller@4001e000/flash@0/partitions/partition@0' defined in zephyr/boards/nordic/nrf52dk/nrf52dk_nrf52832.dts:235 */
					boot_partition: partition@0 {
						label = "mcuboot";    /* in zephyr/boards/nordic/nrf52dk/nrf52dk_nrf52832.dts:236 */
						reg = < 0x0 0xc000 >; /* in zephyr/boards/nordic/nrf52dk/nrf52dk_nrf52832.dts:237 */
					};

					/* node '/soc/flash-controller@4001e000/flash@0/partitions/partition@c000' defined in zephyr/boards/nordic/nrf52dk/nrf52dk_nrf52832.dts:240 */
					slot0_partition: partition@c000 {
						label = "image-0";        /* in zephyr/boards/nordic/nrf52dk/nrf52dk_nrf52832.dts:241 */
						reg = < 0xc000 0x37000 >; /* in zephyr/boards/nordic/nrf52dk/nrf52dk_nrf52832.dts:242 */
					};

					/* node '/soc/flash-controller@4001e000/flash@0/partitions/partition@43000' defined in zephyr/boards/nordic/nrf52dk/nrf52dk_nrf52832.dts:245 */
					slot1_partition: partition@43000 {
						label = "image-1";         /* in zephyr/boards/nordic/nrf52dk/nrf52dk_nrf52832.dts:246 */
						reg = < 0x43000 0x37000 >; /* in zephyr/boards/nordic/nrf52dk/nrf52dk_nrf52832.dts:247 */
					};

					/* node '/soc/flash-controller@4001e000/flash@0/partitions/partition@7a000' defined in zephyr/boards/nordic/nrf52dk/nrf52dk_nrf52832.dts:250 */
					storage_partition: partition@7a000 {
						label = "storage";        /* in zephyr/boards/nordic/nrf52dk/nrf52dk_nrf52832.dts:251 */
						reg = < 0x7a000 0x6000 >; /* in zephyr/boards/nordic/nrf52dk/nrf52dk_nrf52832.dts:252 */
					};
				};
			};
		};

		/* node '/soc/ppi@4001f000' defined in zephyr/dts/arm/nordic/nrf52832.dtsi:432 */
		ppi: ppi@4001f000 {
			compatible = "nordic,nrf-ppi"; /* in zephyr/dts/arm/nordic/nrf52832.dtsi:433 */
			reg = < 0x4001f000 0x1000 >;   /* in zephyr/dts/arm/nordic/nrf52832.dtsi:434 */
			status = "okay";               /* in zephyr/dts/arm/nordic/nrf52832.dtsi:435 */
		};

		/* node '/soc/mwu@40020000' defined in zephyr/dts/arm/nordic/nrf52832.dtsi:438 */
		mwu: mwu@40020000 {
			compatible = "nordic,nrf-mwu"; /* in zephyr/dts/arm/nordic/nrf52832.dtsi:439 */
			reg = < 0x40020000 0x1000 >;   /* in zephyr/dts/arm/nordic/nrf52832.dtsi:440 */
			status = "okay";               /* in zephyr/dts/arm/nordic/nrf52832.dtsi:441 */
		};

		/* node '/soc/pwm@40021000' defined in zephyr/dts/arm/nordic/nrf52832.dtsi:444 */
		pwm1: pwm@40021000 {
			compatible = "nordic,nrf-pwm"; /* in zephyr/dts/arm/nordic/nrf52832.dtsi:445 */
			reg = < 0x40021000 0x1000 >;   /* in zephyr/dts/arm/nordic/nrf52832.dtsi:446 */
			interrupts = < 0x21 0x1 >;     /* in zephyr/dts/arm/nordic/nrf52832.dtsi:447 */
			status = "disabled";           /* in zephyr/dts/arm/nordic/nrf52832.dtsi:448 */
			#pwm-cells = < 0x3 >;          /* in zephyr/dts/arm/nordic/nrf52832.dtsi:449 */
		};

		/* node '/soc/pwm@40022000' defined in zephyr/dts/arm/nordic/nrf52832.dtsi:452 */
		pwm2: pwm@40022000 {
			compatible = "nordic,nrf-pwm"; /* in zephyr/dts/arm/nordic/nrf52832.dtsi:453 */
			reg = < 0x40022000 0x1000 >;   /* in zephyr/dts/arm/nordic/nrf52832.dtsi:454 */
			interrupts = < 0x22 0x1 >;     /* in zephyr/dts/arm/nordic/nrf52832.dtsi:455 */
			status = "disabled";           /* in zephyr/dts/arm/nordic/nrf52832.dtsi:456 */
			#pwm-cells = < 0x3 >;          /* in zephyr/dts/arm/nordic/nrf52832.dtsi:457 */
		};

		/* node '/soc/spi@40023000' defined in zephyr/dts/arm/nordic/nrf52832.dtsi:460 */
		spi2: arduino_spi: spi@40023000 {
			#address-cells = < 0x1 >;                /* in zephyr/dts/arm/nordic/nrf52832.dtsi:469 */
			#size-cells = < 0x0 >;                   /* in zephyr/dts/arm/nordic/nrf52832.dtsi:470 */
			reg = < 0x40023000 0x1000 >;             /* in zephyr/dts/arm/nordic/nrf52832.dtsi:471 */
			interrupts = < 0x23 0x1 >;               /* in zephyr/dts/arm/nordic/nrf52832.dtsi:472 */
			max-frequency = < 0x7a1200 >;            /* in zephyr/dts/arm/nordic/nrf52832.dtsi:473 */
			easydma-maxcnt-bits = < 0x8 >;           /* in zephyr/dts/arm/nordic/nrf52832.dtsi:474 */
			compatible = "nordic,nrf-spi";           /* in zephyr/boards/nordic/nrf52dk/nrf52dk_nrf52832.dts:221 */
			status = "okay";                         /* in zephyr/boards/nordic/nrf52dk/nrf52dk_nrf52832.dts:222 */
			cs-gpios = < &arduino_header 0x10 0x1 >; /* in zephyr/boards/nordic/nrf52dk/nrf52dk_nrf52832.dts:223 */
			pinctrl-0 = < &spi2_default >;           /* in zephyr/boards/nordic/nrf52dk/nrf52dk_nrf52832.dts:224 */
			pinctrl-1 = < &spi2_sleep >;             /* in zephyr/boards/nordic/nrf52dk/nrf52dk_nrf52832.dts:225 */
			pinctrl-names = "default",
			                "sleep";                 /* in zephyr/boards/nordic/nrf52dk/nrf52dk_nrf52832.dts:226 */
		};

		/* node '/soc/rtc@40024000' defined in zephyr/dts/arm/nordic/nrf52832.dtsi:478 */
		rtc2: rtc@40024000 {
			compatible = "nordic,nrf-rtc"; /* in zephyr/dts/arm/nordic/nrf52832.dtsi:479 */
			reg = < 0x40024000 0x1000 >;   /* in zephyr/dts/arm/nordic/nrf52832.dtsi:480 */
			cc-num = < 0x4 >;              /* in zephyr/dts/arm/nordic/nrf52832.dtsi:481 */
			interrupts = < 0x24 0x1 >;     /* in zephyr/dts/arm/nordic/nrf52832.dtsi:482 */
			status = "disabled";           /* in zephyr/dts/arm/nordic/nrf52832.dtsi:483 */
			clock-frequency = < 0x8000 >;  /* in zephyr/dts/arm/nordic/nrf52832.dtsi:484 */
			prescaler = < 0x1 >;           /* in zephyr/dts/arm/nordic/nrf52832.dtsi:485 */
		};

		/* node '/soc/i2s@40025000' defined in zephyr/dts/arm/nordic/nrf52832.dtsi:488 */
		i2s0: i2s@40025000 {
			compatible = "nordic,nrf-i2s"; /* in zephyr/dts/arm/nordic/nrf52832.dtsi:489 */
			#address-cells = < 0x1 >;      /* in zephyr/dts/arm/nordic/nrf52832.dtsi:490 */
			#size-cells = < 0x0 >;         /* in zephyr/dts/arm/nordic/nrf52832.dtsi:491 */
			reg = < 0x40025000 0x1000 >;   /* in zephyr/dts/arm/nordic/nrf52832.dtsi:492 */
			interrupts = < 0x25 0x1 >;     /* in zephyr/dts/arm/nordic/nrf52832.dtsi:493 */
			status = "disabled";           /* in zephyr/dts/arm/nordic/nrf52832.dtsi:494 */
		};

		/* node '/soc/gpio@50000000' defined in zephyr/dts/arm/nordic/nrf52832.dtsi:497 */
		gpio0: gpio@50000000 {
			compatible = "nordic,nrf-gpio"; /* in zephyr/dts/arm/nordic/nrf52832.dtsi:498 */
			gpio-controller;                /* in zephyr/dts/arm/nordic/nrf52832.dtsi:499 */
			reg = < 0x50000000 0x1000 >;    /* in zephyr/dts/arm/nordic/nrf52832.dtsi:500 */
			#gpio-cells = < 0x2 >;          /* in zephyr/dts/arm/nordic/nrf52832.dtsi:501 */
			port = < 0x0 >;                 /* in zephyr/dts/arm/nordic/nrf52832.dtsi:503 */
			gpiote-instance = < &gpiote >;  /* in zephyr/dts/arm/nordic/nrf52832.dtsi:504 */
			status = "okay";                /* in zephyr/boards/nordic/nrf52dk/nrf52dk_nrf52832.dts:167 */
			phandle = < 0x13 >;             /* in zephyr/boards/nordic/nrf52dk/nrf52dk_nrf52832.dts:33 */
		};
	};

	/* node '/pin-controller' defined in zephyr/dts/vendor/nordic/nrf_common.dtsi:26 */
	pinctrl: pin-controller {
		compatible = "nordic,nrf-pinctrl"; /* in zephyr/dts/vendor/nordic/nrf_common.dtsi:31 */

		/* node '/pin-controller/uart0_default' defined in zephyr/boards/nordic/nrf52dk/nrf52dk_nrf52832-pinctrl.dtsi:7 */
		uart0_default: uart0_default {
			phandle = < 0x2 >; /* in zephyr/boards/nordic/nrf52dk/nrf52dk_nrf52832.dts:174 */

			/* node '/pin-controller/uart0_default/group1' defined in zephyr/boards/nordic/nrf52dk/nrf52dk_nrf52832-pinctrl.dtsi:8 */
			group1 {
				psels = < 0x7 >,
				        < 0x1000008 >,
				        < 0x2000005 >,
				        < 0x3000006 >; /* in zephyr/boards/nordic/nrf52dk/nrf52dk_nrf52832.dts:259 */
			};
		};

		/* node '/pin-controller/uart0_sleep' defined in zephyr/boards/nordic/nrf52dk/nrf52dk_nrf52832-pinctrl.dtsi:16 */
		uart0_sleep: uart0_sleep {
			phandle = < 0x3 >; /* in zephyr/boards/nordic/nrf52dk/nrf52dk_nrf52832.dts:175 */

			/* node '/pin-controller/uart0_sleep/group1' defined in zephyr/boards/nordic/nrf52dk/nrf52dk_nrf52832-pinctrl.dtsi:17 */
			group1 {
				low-power-enable;      /* in zephyr/boards/nordic/nrf52dk/nrf52dk_nrf52832-pinctrl.dtsi:21 */
				psels = < 0x1000008 >,
				        < 0x2000005 >,
				        < 0x3000006 >; /* in zephyr/boards/nordic/nrf52dk/nrf52dk_nrf52832.dts:272 */
			};

			/* node '/pin-controller/uart0_sleep/group2' defined in zephyr/boards/nordic/nrf52dk/nrf52dk_nrf52832-pinctrl.dtsi:24 */
			group2 {
				low-power-enable; /* in zephyr/boards/nordic/nrf52dk/nrf52dk_nrf52832-pinctrl.dtsi:26 */
				bias-pull-up;     /* in zephyr/boards/nordic/nrf52dk/nrf52dk_nrf52832-pinctrl.dtsi:27 */
				psels = < 0x7 >;  /* in zephyr/boards/nordic/nrf52dk/nrf52dk_nrf52832.dts:268 */
			};
		};

		/* node '/pin-controller/i2c0_default' defined in zephyr/boards/nordic/nrf52dk/nrf52dk_nrf52832-pinctrl.dtsi:31 */
		i2c0_default: i2c0_default {
			phandle = < 0x4 >; /* in zephyr/boards/nordic/nrf52dk/nrf52dk_nrf52832.dts:182 */

			/* node '/pin-controller/i2c0_default/group1' defined in zephyr/boards/nordic/nrf52dk/nrf52dk_nrf52832-pinctrl.dtsi:32 */
			group1 {
				psels = < 0xc00001a >,
				        < 0xb00001b >; /* in zephyr/boards/nordic/nrf52dk/nrf52dk_nrf52832-pinctrl.dtsi:33 */
			};
		};

		/* node '/pin-controller/i2c0_sleep' defined in zephyr/boards/nordic/nrf52dk/nrf52dk_nrf52832-pinctrl.dtsi:38 */
		i2c0_sleep: i2c0_sleep {
			phandle = < 0x5 >; /* in zephyr/boards/nordic/nrf52dk/nrf52dk_nrf52832.dts:183 */

			/* node '/pin-controller/i2c0_sleep/group1' defined in zephyr/boards/nordic/nrf52dk/nrf52dk_nrf52832-pinctrl.dtsi:39 */
			group1 {
				psels = < 0xc00001a >,
				        < 0xb00001b >; /* in zephyr/boards/nordic/nrf52dk/nrf52dk_nrf52832-pinctrl.dtsi:40 */
				low-power-enable;      /* in zephyr/boards/nordic/nrf52dk/nrf52dk_nrf52832-pinctrl.dtsi:42 */
			};
		};

		/* node '/pin-controller/i2c1_default' defined in zephyr/boards/nordic/nrf52dk/nrf52dk_nrf52832-pinctrl.dtsi:46 */
		i2c1_default: i2c1_default {
			phandle = < 0x8 >; /* in zephyr/boards/nordic/nrf52dk/nrf52dk_nrf52832.dts:191 */

			/* node '/pin-controller/i2c1_default/group1' defined in zephyr/boards/nordic/nrf52dk/nrf52dk_nrf52832-pinctrl.dtsi:47 */
			group1 {
				psels = < 0xc00001e >,
				        < 0xb00001f >; /* in zephyr/boards/nordic/nrf52dk/nrf52dk_nrf52832-pinctrl.dtsi:48 */
			};
		};

		/* node '/pin-controller/i2c1_sleep' defined in zephyr/boards/nordic/nrf52dk/nrf52dk_nrf52832-pinctrl.dtsi:53 */
		i2c1_sleep: i2c1_sleep {
			phandle = < 0x9 >; /* in zephyr/boards/nordic/nrf52dk/nrf52dk_nrf52832.dts:192 */

			/* node '/pin-controller/i2c1_sleep/group1' defined in zephyr/boards/nordic/nrf52dk/nrf52dk_nrf52832-pinctrl.dtsi:54 */
			group1 {
				psels = < 0xc00001e >,
				        < 0xb00001f >; /* in zephyr/boards/nordic/nrf52dk/nrf52dk_nrf52832-pinctrl.dtsi:55 */
				low-power-enable;      /* in zephyr/boards/nordic/nrf52dk/nrf52dk_nrf52832-pinctrl.dtsi:57 */
			};
		};

		/* node '/pin-controller/pwm0_default' defined in zephyr/boards/nordic/nrf52dk/nrf52dk_nrf52832-pinctrl.dtsi:61 */
		pwm0_default: pwm0_default {
			phandle = < 0xc >; /* in zephyr/boards/nordic/nrf52dk/nrf52dk_nrf52832.dts:198 */

			/* node '/pin-controller/pwm0_default/group1' defined in zephyr/boards/nordic/nrf52dk/nrf52dk_nrf52832-pinctrl.dtsi:62 */
			group1 {
				psels = < 0x16000011 >; /* in zephyr/boards/nordic/nrf52dk/nrf52dk_nrf52832-pinctrl.dtsi:63 */
				nordic,invert;          /* in zephyr/boards/nordic/nrf52dk/nrf52dk_nrf52832-pinctrl.dtsi:64 */
			};
		};

		/* node '/pin-controller/pwm0_sleep' defined in zephyr/boards/nordic/nrf52dk/nrf52dk_nrf52832-pinctrl.dtsi:68 */
		pwm0_sleep: pwm0_sleep {
			phandle = < 0xd >; /* in zephyr/boards/nordic/nrf52dk/nrf52dk_nrf52832.dts:199 */

			/* node '/pin-controller/pwm0_sleep/group1' defined in zephyr/boards/nordic/nrf52dk/nrf52dk_nrf52832-pinctrl.dtsi:69 */
			group1 {
				psels = < 0x16000011 >; /* in zephyr/boards/nordic/nrf52dk/nrf52dk_nrf52832-pinctrl.dtsi:70 */
				low-power-enable;       /* in zephyr/boards/nordic/nrf52dk/nrf52dk_nrf52832-pinctrl.dtsi:71 */
			};
		};

		/* node '/pin-controller/spi0_default' defined in zephyr/boards/nordic/nrf52dk/nrf52dk_nrf52832-pinctrl.dtsi:75 */
		spi0_default: spi0_default {
			phandle = < 0x6 >; /* in zephyr/boards/nordic/nrf52dk/nrf52dk_nrf52832.dts:207 */

			/* node '/pin-controller/spi0_default/group1' defined in zephyr/boards/nordic/nrf52dk/nrf52dk_nrf52832-pinctrl.dtsi:76 */
			group1 {
				psels = < 0x400001b >,
				        < 0x500001a >,
				        < 0x600001c >; /* in zephyr/boards/nordic/nrf52dk/nrf52dk_nrf52832-pinctrl.dtsi:77 */
			};
		};

		/* node '/pin-controller/spi0_sleep' defined in zephyr/boards/nordic/nrf52dk/nrf52dk_nrf52832-pinctrl.dtsi:83 */
		spi0_sleep: spi0_sleep {
			phandle = < 0x7 >; /* in zephyr/boards/nordic/nrf52dk/nrf52dk_nrf52832.dts:208 */

			/* node '/pin-controller/spi0_sleep/group1' defined in zephyr/boards/nordic/nrf52dk/nrf52dk_nrf52832-pinctrl.dtsi:84 */
			group1 {
				psels = < 0x400001b >,
				        < 0x500001a >,
				        < 0x600001c >; /* in zephyr/boards/nordic/nrf52dk/nrf52dk_nrf52832-pinctrl.dtsi:85 */
				low-power-enable;      /* in zephyr/boards/nordic/nrf52dk/nrf52dk_nrf52832-pinctrl.dtsi:88 */
			};
		};

		/* node '/pin-controller/spi1_default' defined in zephyr/boards/nordic/nrf52dk/nrf52dk_nrf52832-pinctrl.dtsi:92 */
		spi1_default: spi1_default {
			phandle = < 0xa >; /* in zephyr/boards/nordic/nrf52dk/nrf52dk_nrf52832.dts:215 */

			/* node '/pin-controller/spi1_default/group1' defined in zephyr/boards/nordic/nrf52dk/nrf52dk_nrf52832-pinctrl.dtsi:93 */
			group1 {
				psels = < 0x400001f >,
				        < 0x500001e >,
				        < 0x600001d >; /* in zephyr/boards/nordic/nrf52dk/nrf52dk_nrf52832-pinctrl.dtsi:94 */
			};
		};

		/* node '/pin-controller/spi1_sleep' defined in zephyr/boards/nordic/nrf52dk/nrf52dk_nrf52832-pinctrl.dtsi:100 */
		spi1_sleep: spi1_sleep {
			phandle = < 0xb >; /* in zephyr/boards/nordic/nrf52dk/nrf52dk_nrf52832.dts:216 */

			/* node '/pin-controller/spi1_sleep/group1' defined in zephyr/boards/nordic/nrf52dk/nrf52dk_nrf52832-pinctrl.dtsi:101 */
			group1 {
				psels = < 0x400001f >,
				        < 0x500001e >,
				        < 0x600001d >; /* in zephyr/boards/nordic/nrf52dk/nrf52dk_nrf52832-pinctrl.dtsi:102 */
				low-power-enable;      /* in zephyr/boards/nordic/nrf52dk/nrf52dk_nrf52832-pinctrl.dtsi:105 */
			};
		};

		/* node '/pin-controller/spi2_default' defined in zephyr/boards/nordic/nrf52dk/nrf52dk_nrf52832-pinctrl.dtsi:109 */
		spi2_default: spi2_default {
			phandle = < 0xf >; /* in zephyr/boards/nordic/nrf52dk/nrf52dk_nrf52832.dts:224 */

			/* node '/pin-controller/spi2_default/group1' defined in zephyr/boards/nordic/nrf52dk/nrf52dk_nrf52832-pinctrl.dtsi:110 */
			group1 {
				psels = < 0x4000019 >,
				        < 0x5000017 >,
				        < 0x6000018 >;       /* in zephyr/boards/nordic/nrf52dk/nrf52dk_nrf52832-pinctrl.dtsi:111 */
				nordic,drive-mode = < 0x3 >; /* in zephyr/boards/nordic/nrf52dk/nrf52dk_nrf52832-pinctrl.dtsi:114 */
			};
		};

		/* node '/pin-controller/spi2_sleep' defined in zephyr/boards/nordic/nrf52dk/nrf52dk_nrf52832-pinctrl.dtsi:118 */
		spi2_sleep: spi2_sleep {
			phandle = < 0x10 >; /* in zephyr/boards/nordic/nrf52dk/nrf52dk_nrf52832.dts:225 */

			/* node '/pin-controller/spi2_sleep/group1' defined in zephyr/boards/nordic/nrf52dk/nrf52dk_nrf52832-pinctrl.dtsi:119 */
			group1 {
				psels = < 0x4000019 >,
				        < 0x5000017 >,
				        < 0x6000018 >; /* in zephyr/boards/nordic/nrf52dk/nrf52dk_nrf52832-pinctrl.dtsi:120 */
				low-power-enable;      /* in zephyr/boards/nordic/nrf52dk/nrf52dk_nrf52832-pinctrl.dtsi:123 */
			};
		};
	};

	/* node '/entropy_bt_hci' defined in zephyr/dts/vendor/nordic/nrf_common.dtsi:34 */
	rng_hci: entropy_bt_hci {
		compatible = "zephyr,bt-hci-entropy"; /* in zephyr/dts/vendor/nordic/nrf_common.dtsi:35 */
		status = "disabled";                  /* in zephyr/dts/vendor/nordic/nrf_common.dtsi:36 */
	};

	/* node '/sw-pwm' defined in zephyr/dts/vendor/nordic/nrf_common.dtsi:39 */
	sw_pwm: sw-pwm {
		compatible = "nordic,nrf-sw-pwm"; /* in zephyr/dts/vendor/nordic/nrf_common.dtsi:40 */
		status = "disabled";              /* in zephyr/dts/vendor/nordic/nrf_common.dtsi:41 */
		generator = < &timer1 >;          /* in zephyr/dts/vendor/nordic/nrf_common.dtsi:42 */
		clock-prescaler = < 0x0 >;        /* in zephyr/dts/vendor/nordic/nrf_common.dtsi:43 */
		#pwm-cells = < 0x3 >;             /* in zephyr/dts/vendor/nordic/nrf_common.dtsi:44 */
	};

	/* node '/cpus' defined in zephyr/dts/arm/nordic/nrf52832.dtsi:19 */
	cpus {
		#address-cells = < 0x1 >; /* in zephyr/dts/arm/nordic/nrf52832.dtsi:20 */
		#size-cells = < 0x0 >;    /* in zephyr/dts/arm/nordic/nrf52832.dtsi:21 */

		/* node '/cpus/cpu@0' defined in zephyr/dts/arm/nordic/nrf52832.dtsi:23 */
		cpu@0 {
			device_type = "cpu";           /* in zephyr/dts/arm/nordic/nrf52832.dtsi:24 */
			compatible = "arm,cortex-m4f"; /* in zephyr/dts/arm/nordic/nrf52832.dtsi:25 */
			reg = < 0x0 >;                 /* in zephyr/dts/arm/nordic/nrf52832.dtsi:26 */
			#address-cells = < 0x1 >;      /* in zephyr/dts/arm/nordic/nrf52832.dtsi:27 */
			#size-cells = < 0x1 >;         /* in zephyr/dts/arm/nordic/nrf52832.dtsi:28 */

			/* node '/cpus/cpu@0/itm@e0000000' defined in zephyr/dts/arm/nordic/nrf52832.dtsi:30 */
			itm: itm@e0000000 {
				compatible = "arm,armv7m-itm";     /* in zephyr/dts/arm/nordic/nrf52832.dtsi:31 */
				reg = < 0xe0000000 0x1000 >;       /* in zephyr/dts/arm/nordic/nrf52832.dtsi:32 */
				swo-ref-frequency = < 0x1e84800 >; /* in zephyr/dts/arm/nordic/nrf52832.dtsi:33 */
			};
		};
	};

	/* node '/clocks' defined in zephyr/dts/arm/nordic/nrf52832.dtsi:38 */
	clocks {

		/* node '/clocks/hfxo' defined in zephyr/dts/arm/nordic/nrf52832.dtsi:39 */
		hfxo: hfxo {
			compatible = "nordic,nrf52-hfxo"; /* in zephyr/dts/arm/nordic/nrf52832.dtsi:40 */
			clock-frequency = < 0x3d09000 >;  /* in zephyr/dts/arm/nordic/nrf52832.dtsi:41 */
			startup-time-us = < 0x578 >;      /* in zephyr/dts/arm/nordic/nrf52832.dtsi:42 */
			#clock-cells = < 0x0 >;           /* in zephyr/dts/arm/nordic/nrf52832.dtsi:43 */
		};
	};

	/* node '/leds' defined in zephyr/boards/nordic/nrf52dk/nrf52dk_nrf52832.dts:29 */
	leds {
		compatible = "gpio-leds"; /* in zephyr/boards/nordic/nrf52dk/nrf52dk_nrf52832.dts:30 */

		/* node '/leds/led_0' defined in zephyr/boards/nordic/nrf52dk/nrf52dk_nrf52832.dts:32 */
		led0: led_0 {
			gpios = < &gpio0 0x11 0x1 >; /* in zephyr/boards/nordic/nrf52dk/nrf52dk_nrf52832.dts:33 */
			label = "Green LED 0";       /* in zephyr/boards/nordic/nrf52dk/nrf52dk_nrf52832.dts:34 */
		};

		/* node '/leds/led_1' defined in zephyr/boards/nordic/nrf52dk/nrf52dk_nrf52832.dts:37 */
		led1: led_1 {
			gpios = < &gpio0 0x12 0x1 >; /* in zephyr/boards/nordic/nrf52dk/nrf52dk_nrf52832.dts:38 */
			label = "Green LED 1";       /* in zephyr/boards/nordic/nrf52dk/nrf52dk_nrf52832.dts:39 */
		};

		/* node '/leds/led_2' defined in zephyr/boards/nordic/nrf52dk/nrf52dk_nrf52832.dts:42 */
		led2: led_2 {
			gpios = < &gpio0 0x13 0x1 >; /* in zephyr/boards/nordic/nrf52dk/nrf52dk_nrf52832.dts:43 */
			label = "Green LED 2";       /* in zephyr/boards/nordic/nrf52dk/nrf52dk_nrf52832.dts:44 */
		};

		/* node '/leds/led_3' defined in zephyr/boards/nordic/nrf52dk/nrf52dk_nrf52832.dts:47 */
		led3: led_3 {
			gpios = < &gpio0 0x14 0x1 >; /* in zephyr/boards/nordic/nrf52dk/nrf52dk_nrf52832.dts:48 */
			label = "Green LED 3";       /* in zephyr/boards/nordic/nrf52dk/nrf52dk_nrf52832.dts:49 */
		};
	};

	/* node '/pwmleds' defined in zephyr/boards/nordic/nrf52dk/nrf52dk_nrf52832.dts:53 */
	pwmleds {
		compatible = "pwm-leds"; /* in zephyr/boards/nordic/nrf52dk/nrf52dk_nrf52832.dts:54 */

		/* node '/pwmleds/pwm_led_0' defined in zephyr/boards/nordic/nrf52dk/nrf52dk_nrf52832.dts:56 */
		pwm_led0: pwm_led_0 {
			pwms = < &pwm0 0x0 0x1312d00 0x1 >; /* in zephyr/boards/nordic/nrf52dk/nrf52dk_nrf52832.dts:57 */
		};
	};

	/* node '/buttons' defined in zephyr/boards/nordic/nrf52dk/nrf52dk_nrf52832.dts:61 */
	buttons {
		compatible = "gpio-keys"; /* in zephyr/boards/nordic/nrf52dk/nrf52dk_nrf52832.dts:62 */

		/* node '/buttons/button_0' defined in zephyr/boards/nordic/nrf52dk/nrf52dk_nrf52832.dts:64 */
		button0: button_0 {
			gpios = < &gpio0 0xd 0x11 >;    /* in zephyr/boards/nordic/nrf52dk/nrf52dk_nrf52832.dts:65 */
			label = "Push button switch 0"; /* in zephyr/boards/nordic/nrf52dk/nrf52dk_nrf52832.dts:66 */
			zephyr,code = < 0xb >;          /* in zephyr/boards/nordic/nrf52dk/nrf52dk_nrf52832.dts:67 */
		};

		/* node '/buttons/button_1' defined in zephyr/boards/nordic/nrf52dk/nrf52dk_nrf52832.dts:70 */
		button1: button_1 {
			gpios = < &gpio0 0xe 0x11 >;    /* in zephyr/boards/nordic/nrf52dk/nrf52dk_nrf52832.dts:71 */
			label = "Push button switch 1"; /* in zephyr/boards/nordic/nrf52dk/nrf52dk_nrf52832.dts:72 */
			zephyr,code = < 0x2 >;          /* in zephyr/boards/nordic/nrf52dk/nrf52dk_nrf52832.dts:73 */
		};

		/* node '/buttons/button_2' defined in zephyr/boards/nordic/nrf52dk/nrf52dk_nrf52832.dts:76 */
		button2: button_2 {
			gpios = < &gpio0 0xf 0x11 >;    /* in zephyr/boards/nordic/nrf52dk/nrf52dk_nrf52832.dts:77 */
			label = "Push button switch 2"; /* in zephyr/boards/nordic/nrf52dk/nrf52dk_nrf52832.dts:78 */
			zephyr,code = < 0x3 >;          /* in zephyr/boards/nordic/nrf52dk/nrf52dk_nrf52832.dts:79 */
		};

		/* node '/buttons/button_3' defined in zephyr/boards/nordic/nrf52dk/nrf52dk_nrf52832.dts:82 */
		button3: button_3 {
			gpios = < &gpio0 0x10 0x11 >;   /* in zephyr/boards/nordic/nrf52dk/nrf52dk_nrf52832.dts:83 */
			label = "Push button switch 3"; /* in zephyr/boards/nordic/nrf52dk/nrf52dk_nrf52832.dts:84 */
			zephyr,code = < 0x4 >;          /* in zephyr/boards/nordic/nrf52dk/nrf52dk_nrf52832.dts:85 */
		};
	};

	/* node '/connector' defined in zephyr/boards/nordic/nrf52dk/nrf52dk_nrf52832.dts:89 */
	arduino_header: connector {
		compatible = "arduino-header-r3";          /* in zephyr/boards/nordic/nrf52dk/nrf52dk_nrf52832.dts:90 */
		#gpio-cells = < 0x2 >;                     /* in zephyr/boards/nordic/nrf52dk/nrf52dk_nrf52832.dts:91 */
		gpio-map-mask = < 0xffffffff 0xffffffc0 >; /* in zephyr/boards/nordic/nrf52dk/nrf52dk_nrf52832.dts:92 */
		gpio-map-pass-thru = < 0x0 0x3f >;         /* in zephyr/boards/nordic/nrf52dk/nrf52dk_nrf52832.dts:93 */
		gpio-map = < 0x0 0x0 &gpio0 0x3 0x0 >,
		           < 0x1 0x0 &gpio0 0x4 0x0 >,
		           < 0x2 0x0 &gpio0 0x1c 0x0 >,
		           < 0x3 0x0 &gpio0 0x1d 0x0 >,
		           < 0x4 0x0 &gpio0 0x1e 0x0 >,
		           < 0x5 0x0 &gpio0 0x1f 0x0 >,
		           < 0x6 0x0 &gpio0 0xb 0x0 >,
		           < 0x7 0x0 &gpio0 0xc 0x0 >,
		           < 0x8 0x0 &gpio0 0xd 0x0 >,
		           < 0x9 0x0 &gpio0 0xe 0x0 >,
		           < 0xa 0x0 &gpio0 0xf 0x0 >,
		           < 0xb 0x0 &gpio0 0x10 0x0 >,
		           < 0xc 0x0 &gpio0 0x11 0x0 >,
		           < 0xd 0x0 &gpio0 0x12 0x0 >,
		           < 0xe 0x0 &gpio0 0x13 0x0 >,
		           < 0xf 0x0 &gpio0 0x14 0x0 >,
		           < 0x10 0x0 &gpio0 0x16 0x0 >,
		           < 0x11 0x0 &gpio0 0x17 0x0 >,
		           < 0x12 0x0 &gpio0 0x18 0x0 >,
		           < 0x13 0x0 &gpio0 0x19 0x0 >,
		           < 0x14 0x0 &gpio0 0x1a 0x0 >,
		           < 0x15 0x0 &gpio0 0x1b 0x0 >;   /* in zephyr/boards/nordic/nrf52dk/nrf52dk_nrf52832.dts:94 */
		phandle = < 0xe >;                         /* in zephyr/boards/nordic/nrf52dk/nrf52dk_nrf52832.dts:223 */
	};

	/* node '/analog-connector' defined in zephyr/boards/nordic/nrf52dk/nrf52dk_nrf52832.dts:118 */
	arduino_adc: analog-connector {
		compatible = "arduino,uno-adc";    /* in zephyr/boards/nordic/nrf52dk/nrf52dk_nrf52832.dts:119 */
		#io-channel-cells = < 0x1 >;       /* in zephyr/boards/nordic/nrf52dk/nrf52dk_nrf52832.dts:120 */
		io-channel-map = < 0x0 &adc 0x1 >,
		                 < 0x1 &adc 0x2 >,
		                 < 0x2 &adc 0x4 >,
		                 < 0x3 &adc 0x5 >,
		                 < 0x4 &adc 0x6 >,
		                 < 0x5 &adc 0x7 >; /* in zephyr/boards/nordic/nrf52dk/nrf52dk_nrf52832.dts:121 */
	};
};
